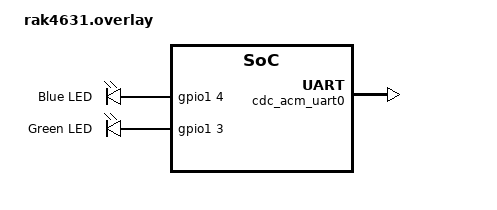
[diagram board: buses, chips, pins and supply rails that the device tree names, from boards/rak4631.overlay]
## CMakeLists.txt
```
# SPDX-License-Identifier: Apache-2.0

cmake_minimum_required(VERSION 3.20.0)

find_package(Zephyr REQUIRED HINTS $ENV{ZEPHYR_BASE})
project(blinky)

target_sources(app PRIVATE src/main.c)
if(CONFIG_USE_SEGGER_RTT AND CONFIG_BOARD_RAK11720)
  target_sources(app PRIVATE src/rtt.c)
endif()
```

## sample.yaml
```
sample:
  name: Blinky
tests:
  sample.basic.blinky:
    platform_allow:
      - rak3112/esp32s3/procpu
      - rak3172
      - rak4631
      - rak5010
      - rak11160
      - rak11720
    tags: rak
    build_only: true
```

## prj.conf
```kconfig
CONFIG_GPIO=y

CONFIG_LOG=y
CONFIG_LOG_PRINTK=n
CONFIG_LOG_MODE_IMMEDIATE=y
# Open following lines to
# use RTT logging for debug!!!
# CONFIG_USE_SEGGER_RTT=y
# CONFIG_LOG_BACKEND_RTT=y
# CONFIG_LOG_BACKEND_UART=n
```

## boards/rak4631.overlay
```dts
/ {
	chosen {
		zephyr,console = &cdc_acm_uart0;
	};

	aliases {
		blue-led = &blue_led;
		green-led = &green_led;
	};

	leds {
		compatible = "gpio-leds";
		blue_led: led_2 {
			gpios = <&gpio1 4 GPIO_ACTIVE_HIGH>;
			label = "Blue LED";
		};
		green_led: led_1 {
			gpios = <&gpio1 3 GPIO_ACTIVE_HIGH>;
			label = "Green LED";
		};
	};
};

&reg1 {
	regulator-initial-mode = <NRF5X_REG_MODE_DCDC>;
};

&zephyr_udc0 {
	cdc_acm_uart0: cdc_acm_uart0 {
		compatible = "zephyr,cdc-acm-uart";
	};
};
```

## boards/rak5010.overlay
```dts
/ {
	chosen {
		zephyr,console = &cdc_acm_uart0;
	};

	aliases {
		green-led = &green_led;
	};

	leds {
		compatible = "gpio-leds";
		green_led: led_1 {
			gpios = <&gpio0 12 GPIO_ACTIVE_HIGH>;
			label = "Green LED";
		};
	};
};

&zephyr_udc0 {
	cdc_acm_uart0: cdc_acm_uart0 {
		compatible = "zephyr,cdc-acm-uart";
	};
};
```

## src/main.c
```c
#include <zephyr/kernel.h>
#include <zephyr/drivers/gpio.h>

#include <zephyr/logging/log.h>
LOG_MODULE_REGISTER(main, LOG_LEVEL_INF);

/* 1000 msec = 1 sec */
#define SLEEP_TIME_MS 1000

/*
 * A build error on this line means your board is unsupported.
 * See the sample documentation for information on how to fix this.
 */
static const struct gpio_dt_spec led = GPIO_DT_SPEC_GET(DT_ALIAS(green_led), gpios);

int main(void)
{
	bool led_state = false;

	if (!gpio_is_ready_dt(&led)) {
		LOG_ERR("LED is not ready!");
	}

	int ret = gpio_pin_configure_dt(&led, GPIO_OUTPUT_ACTIVE);
	if (ret) {
		LOG_ERR("Failed to configure LED!");
	}

	ret = gpio_pin_set_dt(&led, 1); // ON
	if (ret) {
		LOG_ERR("Failed to control LED!");
	}

	k_msleep(1000);

	ret = gpio_pin_set_dt(&led, 0); // OFF
	if (ret) {
		LOG_ERR("Failed to control LED!");
	}

	LOG_INF("Blinky! %s", CONFIG_BOARD);

	while (1) {
		gpio_pin_toggle_dt(&led);
		led_state = !led_state;
		LOG_INF("LED state: %s", led_state ? "ON" : "OFF");

		k_msleep(SLEEP_TIME_MS);
	}

	return 0;
}
```
